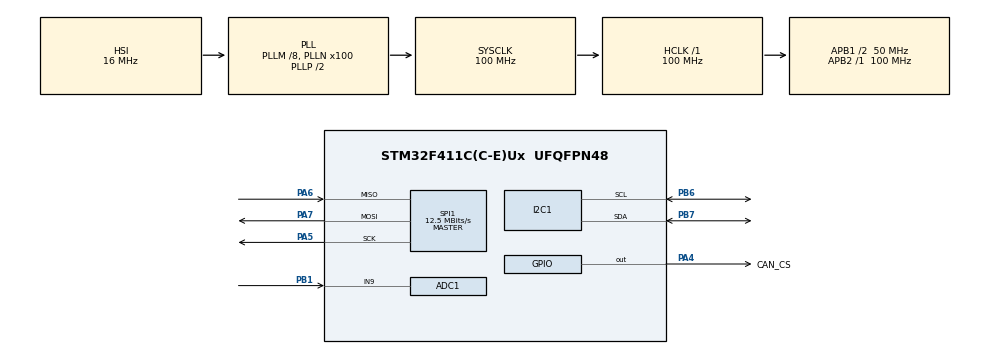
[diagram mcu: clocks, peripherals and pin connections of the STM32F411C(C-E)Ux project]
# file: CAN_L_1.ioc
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ADC1.Channel-0\#ChannelRegularConversion=ADC_CHANNEL_9
ADC1.NbrOfConversionFlag=1
ADC1.Rank-0\#ChannelRegularConversion=1
ADC1.SamplingTime-0\#ChannelRegularConversion=ADC_SAMPLETIME_3CYCLES
ADC1.master=1
I2C1.I2C_Mode=I2C_Fast
Mcu.Family=STM32F4
Mcu.Name=STM32F411C(C-E)Ux
Mcu.Package=UFQFPN48
NVIC.PriorityGroup=NVIC_PRIORITYGROUP_4
PA13.Mode=Serial_Wire
PA13.Signal=SYS_JTMS-SWDIO
PA14.Mode=Serial_Wire
PA14.Signal=SYS_JTCK-SWCLK
PA4.GPIO_Label=CAN_CS
PA4.Signal=GPIO_Output
PA5.Mode=Full_Duplex_Master
PA5.Signal=SPI1_SCK
PA6.Mode=Full_Duplex_Master
PA6.Signal=SPI1_MISO
PA7.Mode=Full_Duplex_Master
PA7.Signal=SPI1_MOSI
PB1.Signal=ADCx_IN9
PB6.Mode=I2C
PB6.Signal=I2C1_SCL
PB7.Mode=I2C
PB7.Signal=I2C1_SDA
PH0\ -\ OSC_IN.Mode=HSE-External-Oscillator
PH0\ -\ OSC_IN.Signal=RCC_OSC_IN
PH1\ -\ OSC_OUT.Mode=HSE-External-Oscillator
PH1\ -\ OSC_OUT.Signal=RCC_OSC_OUT
ProjectManager.HeapSize=0x200
ProjectManager.StackSize=0x400
ProjectManager.TargetToolchain=STM32CubeIDE
RCC.48MHZClocksFreq_Value=50000000
RCC.AHBFreq_Value=100000000
RCC.APB1CLKDivider=RCC_HCLK_DIV2
RCC.APB1Freq_Value=50000000
RCC.APB1TimFreq_Value=100000000
RCC.APB2Freq_Value=100000000
RCC.APB2TimFreq_Value=100000000
RCC.CortexFreq_Value=100000000
RCC.HCLKFreq_Value=100000000
RCC.HSE_VALUE=25000000
RCC.HSI_VALUE=16000000
RCC.LSE_VALUE=32768
RCC.PLLM=8
RCC.PLLN=100
RCC.SYSCLKFreq_VALUE=100000000
RCC.SYSCLKSource=RCC_SYSCLKSOURCE_PLLCLK
RCC.VCOOutputFreq_Value=200000000
SH.ADCx_IN9.0=ADC1_IN9,IN9
SPI1.BaudRatePrescaler=SPI_BAUDRATEPRESCALER_8
SPI1.CalculateBaudRate=12.5 MBits/s
SPI1.Direction=SPI_DIRECTION_2LINES
SPI1.Mode=SPI_MODE_MASTER
SPI1.VirtualType=VM_MASTER
board=custom

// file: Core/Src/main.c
/* USER CODE BEGIN Header */
/**
  ******************************************************************************
  * @file           : main.c
  * @brief          : Main program body
  ******************************************************************************
  * @attention
  *
  * Copyright (c) 2026 STMicroelectronics.
  * All rights reserved.
  *
  * This software is licensed under terms that can be found in the LICENSE file
  * in the root directory of this software component.
  * If no LICENSE file comes with this software, it is provided AS-IS.
  *
  ******************************************************************************
  */
/* USER CODE END Header */
#include "main.h"

/* USER CODE BEGIN Includes */
#include "fonts.h"
#include "ssd1306.h"
#include "CANSPI.h"
/* USER CODE END Includes */

ADC_HandleTypeDef hadc1;

I2C_HandleTypeDef hi2c1;

SPI_HandleTypeDef hspi1;

void SystemClock_Config(void);
static void MX_GPIO_Init(void);
static void MX_I2C1_Init(void);
static void MX_SPI1_Init(void);
static void MX_ADC1_Init(void);

int main(void)
{

  /* MCU Configuration--------------------------------------------------------*/

  /* Reset of all peripherals, Initializes the Flash interface and the Systick. */
  HAL_Init();

  /* Configure the system clock */
  SystemClock_Config();

  /* Initialize all configured peripherals */
  MX_GPIO_Init();
  MX_I2C1_Init();
  MX_SPI1_Init();
  MX_ADC1_Init();
  /* USER CODE BEGIN 2 */

//  uint16_t readValue;
//   uint16_t rxValue;
 // char sstr[5];
//   char snum[5];
  //
   uCAN_MSG txMessage;
   uCAN_MSG rxMessage;
   HAL_ADC_Start(&hadc1);
   CANSPI_Initialize();
   SSD1306_Init();
   SSD1306_GotoXY (0,0);
   SSD1306_Puts ("Olt", &Font_11x18, 1);
   SSD1306_UpdateScreen();
   HAL_Delay(1000);

  /* USER CODE END 2 */

  /* Infinite loop */
  while (1)
  {
//	  HAL_ADC_PollForConversion(&hadc1,1000);
//	     readValue = HAL_ADC_GetValue(&hadc1);
	 // SSD1306_Clear();

	  //SSD1306_Puts ("OLED while1 Test", &Font_11x18, 1);
	  SSD1306_UpdateScreen();
	     txMessage.frame.idType = dSTANDARD_CAN_MSG_ID_2_0B;
	     txMessage.frame.id = 0x127; // ID can be between Hex1 and Hex7FF (1-2047 decimal)
//	     txMessage.frame.dlc = 8;
//	     txMessage.frame.data0 = 'S';
//	     txMessage.frame.data1 = 'T';
//	     txMessage.frame.data2 = 'M';
//	     txMessage.frame.data3 = '3';
//	     txMessage.frame.data4 = '2';
//	     txMessage.frame.data5 = '-';
//	     txMessage.frame.data6 = '0';//readValue & 0xff;
//	     txMessage.frame.data7 = '0';//readValue >> 8;

	     txMessage.frame.dlc = 5;
	     txMessage.frame.data0 = 'S';
	     txMessage.frame.data1 = 'T';
	     txMessage.frame.data2 = 'M';
	     txMessage.frame.data3 = '3';
	     txMessage.frame.data4 = '2';
	     CANSPI_Transmit(&txMessage);
//
////	     if(CANSPI_Receive(&rxMessage))
//	     {
//	         sstr[0] = rxMessage.frame.data0;
//	         sstr[1] = rxMessage.frame.data1;
//	         sstr[2] = rxMessage.frame.data2;
//	         sstr[3] = rxMessage.frame.data3;
//	         sstr[4] = rxMessage.frame.data4;
//	         sstr[5] = ' ';
//	         rxValue = ((uint16_t)rxMessage.frame.data7 << 8) | rxMessage.frame.data6;
//	         itoa(rxValue, snum, 10);
//	         SSD1306_Clear();
//	         SSD1306_GotoXY (0, 0);
//	         SSD1306_Puts (sstr, &Font_11x18, 1);
//	         SSD1306_GotoXY (0, 30);
//	         SSD1306_Puts (snum, &Font_11x18, 1);
	         //SSD1306_UpdateScreen();
	     //SSD1306_Puts ("OLED while Test", &Font_11x18, 1);
	     char sstr[6];
//
	     if(CANSPI_Receive(&rxMessage))
	     {
	         uint8_t *dataPtr = &rxMessage.frame.data0;

	         for(int i = 0; i < rxMessage.frame.dlc; i++)
	         {
	             sstr[i] = dataPtr[i];
	         }

	         sstr[rxMessage.frame.dlc] = '\0';
	         SSD1306_UpdateScreen();
	         SSD1306_Puts ("OLED rx Test", &Font_11x18, 1);

	         SSD1306_Clear();
	         SSD1306_GotoXY(0,0);
	         SSD1306_UpdateScreen();
	         SSD1306_Puts(sstr, &Font_11x18, 1);

	     }
//	     }
	     HAL_Delay(100);
	     /* USER CODE END WHILE */
  }
}

void SystemClock_Config(void)
{
  RCC_OscInitTypeDef RCC_OscInitStruct = {0};
  RCC_ClkInitTypeDef RCC_ClkInitStruct = {0};

  /** Configure the main internal regulator output voltage
  */
  __HAL_RCC_PWR_CLK_ENABLE();
  __HAL_PWR_VOLTAGESCALING_CONFIG(PWR_REGULATOR_VOLTAGE_SCALE1);

  /** Initializes the RCC Oscillators according to the specified parameters
  * in the RCC_OscInitTypeDef structure.
  */
  RCC_OscInitStruct.OscillatorType = RCC_OSCILLATORTYPE_HSI;
  RCC_OscInitStruct.HSIState = RCC_HSI_ON;
  RCC_OscInitStruct.HSICalibrationValue = RCC_HSICALIBRATION_DEFAULT;
  RCC_OscInitStruct.PLL.PLLState = RCC_PLL_ON;
  RCC_OscInitStruct.PLL.PLLSource = RCC_PLLSOURCE_HSI;
  RCC_OscInitStruct.PLL.PLLM = 8;
  RCC_OscInitStruct.PLL.PLLN = 100;
  RCC_OscInitStruct.PLL.PLLP = RCC_PLLP_DIV2;
  RCC_OscInitStruct.PLL.PLLQ = 4;
  if (HAL_RCC_OscConfig(&RCC_OscInitStruct) != HAL_OK)
  {
    Error_Handler();
  }

  /** Initializes the CPU, AHB and APB buses clocks
  */
  RCC_ClkInitStruct.ClockType = RCC_CLOCKTYPE_HCLK|RCC_CLOCKTYPE_SYSCLK
                              |RCC_CLOCKTYPE_PCLK1|RCC_CLOCKTYPE_PCLK2;
  RCC_ClkInitStruct.SYSCLKSource = RCC_SYSCLKSOURCE_PLLCLK;
  RCC_ClkInitStruct.AHBCLKDivider = RCC_SYSCLK_DIV1;
  RCC_ClkInitStruct.APB1CLKDivider = RCC_HCLK_DIV2;
  RCC_ClkInitStruct.APB2CLKDivider = RCC_HCLK_DIV1;

  if (HAL_RCC_ClockConfig(&RCC_ClkInitStruct, FLASH_LATENCY_3) != HAL_OK)
  {
    Error_Handler();
  }
}

static void MX_ADC1_Init(void)
{

  ADC_ChannelConfTypeDef sConfig = {0};

  /** Configure the global features of the ADC (Clock, Resolution, Data Alignment and number of conversion)
  */
  hadc1.Instance = ADC1;
  hadc1.Init.ClockPrescaler = ADC_CLOCK_SYNC_PCLK_DIV4;
  hadc1.Init.Resolution = ADC_RESOLUTION_12B;
  hadc1.Init.ScanConvMode = DISABLE;
  hadc1.Init.ContinuousConvMode = DISABLE;
  hadc1.Init.DiscontinuousConvMode = DISABLE;
  hadc1.Init.ExternalTrigConvEdge = ADC_EXTERNALTRIGCONVEDGE_NONE;
  hadc1.Init.ExternalTrigConv = ADC_SOFTWARE_START;
  hadc1.Init.DataAlign = ADC_DATAALIGN_RIGHT;
  hadc1.Init.NbrOfConversion = 1;
  hadc1.Init.DMAContinuousRequests = DISABLE;
  hadc1.Init.EOCSelection = ADC_EOC_SINGLE_CONV;
  if (HAL_ADC_Init(&hadc1) != HAL_OK)
  {
    Error_Handler();
  }

  /** Configure for the selected ADC regular channel its corresponding rank in the sequencer and its sample time.
  */
  sConfig.Channel = ADC_CHANNEL_9;
  sConfig.Rank = 1;
  sConfig.SamplingTime = ADC_SAMPLETIME_3CYCLES;
  if (HAL_ADC_ConfigChannel(&hadc1, &sConfig) != HAL_OK)
  {
    Error_Handler();
  }

}

static void MX_I2C1_Init(void)
{

  hi2c1.Instance = I2C1;
  hi2c1.Init.ClockSpeed = 400000;
  hi2c1.Init.DutyCycle = I2C_DUTYCYCLE_2;
  hi2c1.Init.OwnAddress1 = 0;
  hi2c1.Init.AddressingMode = I2C_ADDRESSINGMODE_7BIT;
  hi2c1.Init.DualAddressMode = I2C_DUALADDRESS_DISABLE;
  hi2c1.Init.OwnAddress2 = 0;
  hi2c1.Init.GeneralCallMode = I2C_GENERALCALL_DISABLE;
  hi2c1.Init.NoStretchMode = I2C_NOSTRETCH_DISABLE;
  if (HAL_I2C_Init(&hi2c1) != HAL_OK)
  {
    Error_Handler();
  }

}

static void MX_SPI1_Init(void)
{

  /* SPI1 parameter configuration*/
  hspi1.Instance = SPI1;
  hspi1.Init.Mode = SPI_MODE_MASTER;
  hspi1.Init.Direction = SPI_DIRECTION_2LINES;
  hspi1.Init.DataSize = SPI_DATASIZE_8BIT;
  hspi1.Init.CLKPolarity = SPI_POLARITY_LOW;
  hspi1.Init.CLKPhase = SPI_PHASE_1EDGE;
  hspi1.Init.NSS = SPI_NSS_SOFT;
  hspi1.Init.BaudRatePrescaler = SPI_BAUDRATEPRESCALER_8;
  hspi1.Init.FirstBit = SPI_FIRSTBIT_MSB;
  hspi1.Init.TIMode = SPI_TIMODE_DISABLE;
  hspi1.Init.CRCCalculation = SPI_CRCCALCULATION_DISABLE;
  hspi1.Init.CRCPolynomial = 10;
  if (HAL_SPI_Init(&hspi1) != HAL_OK)
  {
    Error_Handler();
  }

}

static void MX_GPIO_Init(void)
{
  GPIO_InitTypeDef GPIO_InitStruct = {0};

  /* GPIO Ports Clock Enable */
  __HAL_RCC_GPIOH_CLK_ENABLE();
  __HAL_RCC_GPIOA_CLK_ENABLE();
  __HAL_RCC_GPIOB_CLK_ENABLE();

  /*Configure GPIO pin Output Level */
  HAL_GPIO_WritePin(CAN_CS_GPIO_Port, CAN_CS_Pin, GPIO_PIN_RESET);

  /*Configure GPIO pin : CAN_CS_Pin */
  GPIO_InitStruct.Pin = CAN_CS_Pin;
  GPIO_InitStruct.Mode = GPIO_MODE_OUTPUT_PP;
  GPIO_InitStruct.Pull = GPIO_NOPULL;
  GPIO_InitStruct.Speed = GPIO_SPEED_FREQ_LOW;
  HAL_GPIO_Init(CAN_CS_GPIO_Port, &GPIO_InitStruct);

}

void Error_Handler(void)
{
  __disable_irq();
  while (1)
  {
  }
}
